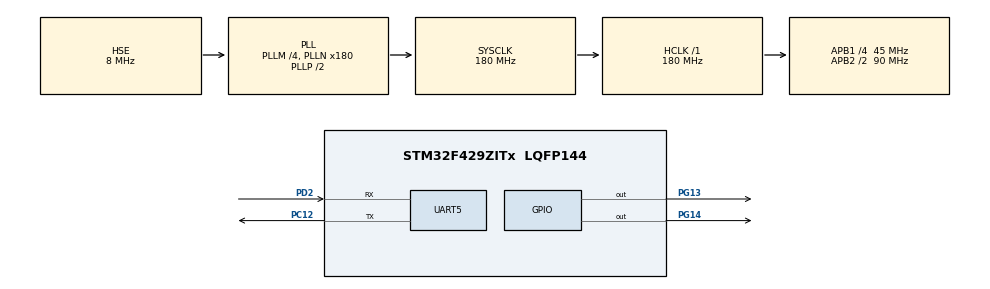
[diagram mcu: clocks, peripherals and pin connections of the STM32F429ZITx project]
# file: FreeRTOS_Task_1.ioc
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FREERTOS.Tasks01=defaultTask,0,128,StartDefaultTask,Default,NULL,Dynamic,NULL,NULL
Mcu.Family=STM32F4
Mcu.Name=STM32F429ZITx
Mcu.Package=LQFP144
NVIC.PriorityGroup=NVIC_PRIORITYGROUP_4
NVIC.TIM6_DAC_IRQn=true\:0\:0\:false\:false\:true\:false\:false\:true
NVIC.TimeBase=TIM6_DAC_IRQn
NVIC.TimeBaseIP=TIM6
PA13.Mode=Serial_Wire
PA13.Signal=SYS_JTMS-SWDIO
PA14.Mode=Serial_Wire
PA14.Signal=SYS_JTCK-SWCLK
PC12.Mode=Asynchronous
PC12.Signal=UART5_TX
PD2.Mode=Asynchronous
PD2.Signal=UART5_RX
PG13.Signal=GPIO_Output
PG14.Signal=GPIO_Output
PH0/OSC_IN.Mode=HSE-External-Oscillator
PH0/OSC_IN.Signal=RCC_OSC_IN
PH1/OSC_OUT.Mode=HSE-External-Oscillator
PH1/OSC_OUT.Signal=RCC_OSC_OUT
ProjectManager.HeapSize=0x200
ProjectManager.StackSize=0x400
ProjectManager.TargetToolchain=STM32CubeIDE
RCC.48MHZClocksFreq_Value=120000000
RCC.AHBFreq_Value=180000000
RCC.APB1CLKDivider=RCC_HCLK_DIV4
RCC.APB1Freq_Value=45000000
RCC.APB1TimFreq_Value=90000000
RCC.APB2CLKDivider=RCC_HCLK_DIV2
RCC.APB2Freq_Value=90000000
RCC.APB2TimFreq_Value=180000000
RCC.CortexFreq_Value=180000000
RCC.HCLKFreq_Value=180000000
RCC.HSE_VALUE=8000000
RCC.HSI_VALUE=16000000
RCC.LSE_VALUE=32768
RCC.PLLM=4
RCC.PLLN=180
RCC.PLLQ=3
RCC.PLLSAIN=50
RCC.PLLSourceVirtual=RCC_PLLSOURCE_HSE
RCC.SYSCLKFreq_VALUE=180000000
RCC.SYSCLKSource=RCC_SYSCLKSOURCE_PLLCLK
RCC.VCOOutputFreq_Value=360000000
UART5.VirtualMode=Asynchronous
VP_FREERTOS_VS_CMSIS_V1.Mode=CMSIS_V1
VP_SYS_VS_tim6.Mode=TIM6
board=STM32F429I-DISC1

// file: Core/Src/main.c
/* USER CODE BEGIN Header */
/**
  ******************************************************************************
  * @file           : main.c
  * @brief          : Main program body
  ******************************************************************************
  * @attention
  *
  * <h2><center>&copy; Copyright (c) 2020 STMicroelectronics.
  * All rights reserved.</center></h2>
  *
  * This software component is licensed by ST under Ultimate Liberty license
  * SLA0044, the "License"; You may not use this file except in compliance with
  * the License. You may obtain a copy of the License at:
  *                             www.st.com/SLA0044
  *
  ******************************************************************************
  */
/* USER CODE END Header */
#include "main.h"
#include "cmsis_os.h"
#include "assert.h"

UART_HandleTypeDef huart5;

osThreadId defaultTaskHandle;
osThreadId uartTaskHandle;

void SystemClock_Config(void);
static void MX_GPIO_Init(void);
static void MX_UART5_Init(void);
void StartDefaultTask(void const * argument);
void StartUartTask(void const * argument);

int main(void)
{

  /* MCU Configuration--------------------------------------------------------*/

  /* Reset of all peripherals, Initializes the Flash interface and the Systick. */
  HAL_Init();

  /* Configure the system clock */
  SystemClock_Config();

  /* Initialize all configured peripherals */
  MX_GPIO_Init();
  MX_UART5_Init();

  /* Create the thread(s) */
  /* definition and creation of defaultTask*/
  osThreadDef(defaultTask, StartDefaultTask, osPriorityNormal, 0, 1024);
  defaultTaskHandle = osThreadCreate(osThread(defaultTask), NULL);

  /* USER CODE BEGIN RTOS_THREADS */
  /* add threads, ... */
  osThreadDef(uartTask,StartUartTask,osPriorityNormal,0,1024);
  uartTaskHandle = osThreadCreate(osThread(uartTask), NULL);
  /* USER CODE END RTOS_THREADS */

  /* Start scheduler */
  osKernelStart();

  /* We should never get here as control is now taken by the scheduler */
  /* Infinite loop */
  while (1)
  {

  }

}
void SystemClock_Config(void)
{
  RCC_OscInitTypeDef RCC_OscInitStruct = {0};
  RCC_ClkInitTypeDef RCC_ClkInitStruct = {0};

  /** Configure the main internal regulator output voltage
  */
  __HAL_RCC_PWR_CLK_ENABLE();
  __HAL_PWR_VOLTAGESCALING_CONFIG(PWR_REGULATOR_VOLTAGE_SCALE1);
  /** Initializes the RCC Oscillators according to the specified parameters
  * in the RCC_OscInitTypeDef structure.
  */
  RCC_OscInitStruct.OscillatorType = RCC_OSCILLATORTYPE_HSE;
  RCC_OscInitStruct.HSEState = RCC_HSE_ON;
  RCC_OscInitStruct.PLL.PLLState = RCC_PLL_ON;
  RCC_OscInitStruct.PLL.PLLSource = RCC_PLLSOURCE_HSE;
  RCC_OscInitStruct.PLL.PLLM = 4;
  RCC_OscInitStruct.PLL.PLLN = 180;
  RCC_OscInitStruct.PLL.PLLP = RCC_PLLP_DIV2;
  RCC_OscInitStruct.PLL.PLLQ = 3;
  if (HAL_RCC_OscConfig(&RCC_OscInitStruct) != HAL_OK)
  {
    Error_Handler();
  }
  /** Activate the Over-Drive mode
  */
  if (HAL_PWREx_EnableOverDrive() != HAL_OK)
  {
    Error_Handler();
  }
  /** Initializes the CPU, AHB and APB buses clocks
  */
  RCC_ClkInitStruct.ClockType = RCC_CLOCKTYPE_HCLK|RCC_CLOCKTYPE_SYSCLK
                              |RCC_CLOCKTYPE_PCLK1|RCC_CLOCKTYPE_PCLK2;
  RCC_ClkInitStruct.SYSCLKSource = RCC_SYSCLKSOURCE_PLLCLK;
  RCC_ClkInitStruct.AHBCLKDivider = RCC_SYSCLK_DIV1;
  RCC_ClkInitStruct.APB1CLKDivider = RCC_HCLK_DIV4;
  RCC_ClkInitStruct.APB2CLKDivider = RCC_HCLK_DIV2;

  if (HAL_RCC_ClockConfig(&RCC_ClkInitStruct, FLASH_LATENCY_5) != HAL_OK)
  {
    Error_Handler();
  }
}

static void MX_UART5_Init(void)
{

  huart5.Instance = UART5;
  huart5.Init.BaudRate = 115200;
  huart5.Init.WordLength = UART_WORDLENGTH_8B;
  huart5.Init.StopBits = UART_STOPBITS_1;
  huart5.Init.Parity = UART_PARITY_NONE;
  huart5.Init.Mode = UART_MODE_TX_RX;
  huart5.Init.HwFlowCtl = UART_HWCONTROL_NONE;
  huart5.Init.OverSampling = UART_OVERSAMPLING_16;
  if (HAL_UART_Init(&huart5) != HAL_OK)
  {
    Error_Handler();
  }

}

static void MX_GPIO_Init(void)
{
  GPIO_InitTypeDef GPIO_InitStruct = {0};

  /* GPIO Ports Clock Enable */
  __HAL_RCC_GPIOH_CLK_ENABLE();
  __HAL_RCC_GPIOA_CLK_ENABLE();
  __HAL_RCC_GPIOC_CLK_ENABLE();
  __HAL_RCC_GPIOD_CLK_ENABLE();
  __HAL_RCC_GPIOG_CLK_ENABLE();

  /*Configure GPIO pin Output Level */
  HAL_GPIO_WritePin(GPIOG, GPIO_PIN_13|GPIO_PIN_14, GPIO_PIN_RESET);

  /*Configure GPIO pins : PG13 PG14 */
  GPIO_InitStruct.Pin = GPIO_PIN_13|GPIO_PIN_14;
  GPIO_InitStruct.Mode = GPIO_MODE_OUTPUT_PP;
  GPIO_InitStruct.Pull = GPIO_NOPULL;
  GPIO_InitStruct.Speed = GPIO_SPEED_FREQ_LOW;
  HAL_GPIO_Init(GPIOG, &GPIO_InitStruct);

}

void StartDefaultTask(void const * argument)
{
  /* USER CODE BEGIN 5 */
  /* Infinite loop */
  for(;;)
  {
    osDelay(100);
  }
  /* USER CODE END 5 */
}

void StartUartTask(void const * argument){

	for(;;){
		osDelay(100);
	}

}
 /**
  * @brief  Period elapsed callback in non blocking mode
  * @note   This function is called  when TIM6 interrupt took place, inside
  * HAL_TIM_IRQHandler(). It makes a direct call to HAL_IncTick() to increment
  * a global variable "uwTick" used as application time base.
  * @param  htim : TIM handle
  * @retval None
  */
void HAL_TIM_PeriodElapsedCallback(TIM_HandleTypeDef *htim)
{
  if (htim->Instance == TIM6) {
    HAL_IncTick();
  }
}

void Error_Handler(void)
{
  __disable_irq();
  while (1)
  {
  }
}

/************************ (C) COPYRIGHT STMicroelectronics *****END OF FILE****/
